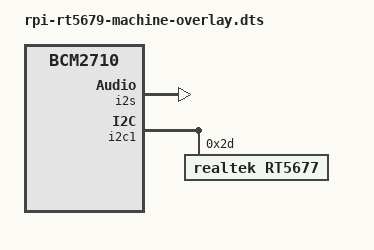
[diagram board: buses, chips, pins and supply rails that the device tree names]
// Definitions for Rpi-Proto
/dts-v1/;
/plugin/;

/ {
	compatible = "brcm,bcm2835", "brcm,bcm2708", "brcm,bcm2710";

	fragment@0 {
		target = <&i2s>;
		__overlay__ {
			status = "okay";
		};
	};

	fragment@1 {
		target = <&i2c1>;
		__overlay__ {
			#address-cells = <1>;
			#size-cells = <0>;
			status = "okay";

			rt5677@2d {
				#sound-dai-cells = <0>;
				compatible = "realtek,rt5677";
				reg = <0x2d>;
				status = "okay";
			};
		};
	};

	fragment@2 {
		target = <&sound>;
		__overlay__ {
			compatible = "rpi,rpi-rt5679-machine";
			i2s-controller = <&i2s>;
			status = "okay";
		};
	};
};
